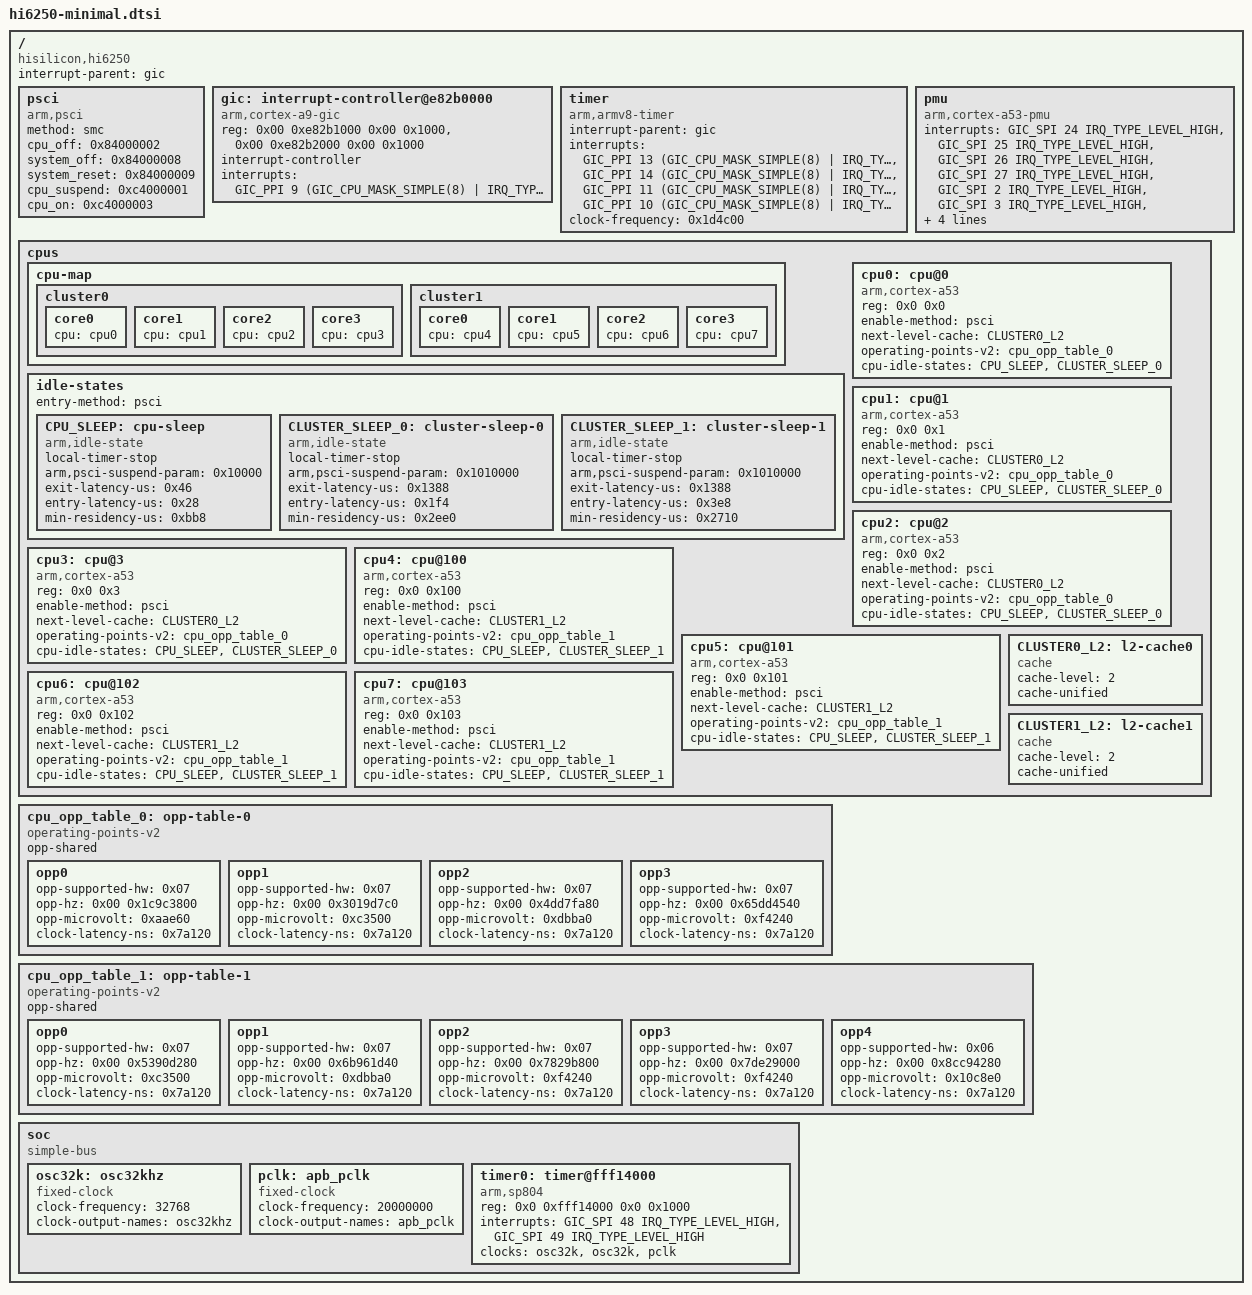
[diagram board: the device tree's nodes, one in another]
// SPDX-License-Identifier: GPL-2.0
/*
 * Minimal device tree of Hisilicon Hi6250 SoC
 *
 * Mostly by @pentiumpro:matrix.org
 */

#include <dt-bindings/interrupt-controller/arm-gic.h>
#include <dt-bindings/gpio/gpio.h>

/ {
	compatible = "hisilicon,hi6250";
	interrupt-parent = <&gic>;
	#address-cells = <2>;
	#size-cells = <2>;

	psci {
		compatible = "arm,psci";
		method = "smc";
		cpu_off = <0x84000002>;
		system_off = <0x84000008>;
		system_reset = <0x84000009>;
		cpu_suspend = <0xc4000001>;
		cpu_on = <0xc4000003>;
	};

	gic: interrupt-controller@e82b0000 {
		compatible = "arm,cortex-a9-gic";
		reg = <0x00 0xe82b1000 0x00 0x1000>,
			  <0x00 0xe82b2000 0x00 0x1000>;
		#interrupt-cells = <0x03>;
		#size-cells = <0x02>;
		#address-cells = <0x02>;
		interrupt-controller;
		interrupts = <GIC_PPI 9 (GIC_CPU_MASK_SIMPLE(8) | IRQ_TYPE_LEVEL_HIGH)>;
		ranges;
	};

	timer {
		compatible = "arm,armv8-timer";
		interrupt-parent = <&gic>;
		interrupts = <GIC_PPI 13 (GIC_CPU_MASK_SIMPLE(8) | IRQ_TYPE_LEVEL_LOW)>,
				 <GIC_PPI 14 (GIC_CPU_MASK_SIMPLE(8) | IRQ_TYPE_LEVEL_LOW)>,
				 <GIC_PPI 11 (GIC_CPU_MASK_SIMPLE(8) | IRQ_TYPE_LEVEL_LOW)>,
				 <GIC_PPI 10 (GIC_CPU_MASK_SIMPLE(8) | IRQ_TYPE_LEVEL_LOW)>;
		clock-frequency = <0x1d4c00>;
	};

	pmu {
		compatible = "arm,cortex-a53-pmu";
		interrupts = <GIC_SPI 24 IRQ_TYPE_LEVEL_HIGH>,
			<GIC_SPI 25 IRQ_TYPE_LEVEL_HIGH>,
			<GIC_SPI 26 IRQ_TYPE_LEVEL_HIGH>,
			<GIC_SPI 27 IRQ_TYPE_LEVEL_HIGH>,
			<GIC_SPI 2 IRQ_TYPE_LEVEL_HIGH>,
			<GIC_SPI 3 IRQ_TYPE_LEVEL_HIGH>,
			<GIC_SPI 4 IRQ_TYPE_LEVEL_HIGH>,
			<GIC_SPI 5 IRQ_TYPE_LEVEL_HIGH>;
		interrupt-affinity = <&cpu0>,
			<&cpu1>,
			<&cpu2>,
			<&cpu3>,
			<&cpu4>,
			<&cpu5>,
			<&cpu6>,
			<&cpu7>;
	};
	
	cpus {
		#address-cells = <2>;
		#size-cells = <0>;

		cpu-map {
			cluster0 {
				core0 {
					cpu = <&cpu0>;
				};
				core1 {
					cpu = <&cpu1>;
				};
				core2 {
					cpu = <&cpu2>;
				};
				core3 {
					cpu = <&cpu3>;
				};
			};
			cluster1 {
				core0 {
					cpu = <&cpu4>;
				};
				core1 {
					cpu = <&cpu5>;
				};
				core2 {
					cpu = <&cpu6>;
				};
				core3 {
					cpu = <&cpu7>;
				};
			};
		};

		idle-states {
			entry-method = "psci";

			CPU_SLEEP: cpu-sleep {
				compatible = "arm,idle-state";
				local-timer-stop;
				arm,psci-suspend-param = <0x10000>;
				exit-latency-us = <0x46>;
				entry-latency-us = <0x28>;
				min-residency-us = <0xbb8>;
			};

			CLUSTER_SLEEP_0: cluster-sleep-0 {
				compatible = "arm,idle-state";
				local-timer-stop;
				arm,psci-suspend-param = <0x1010000>;
				exit-latency-us = <0x1388>;
				entry-latency-us = <0x1f4>;
				min-residency-us = <0x2ee0>;
			};
			
			CLUSTER_SLEEP_1: cluster-sleep-1 {
				compatible = "arm,idle-state";
				local-timer-stop;
				arm,psci-suspend-param = <0x1010000>;
				exit-latency-us = <0x1388>;
				entry-latency-us = <0x3e8>;
				min-residency-us = <0x2710>;
			};
		};

		cpu0: cpu@0 {
			compatible = "arm,cortex-a53";
			device_type = "cpu";
			reg = <0x0 0x0>;
			enable-method = "psci";
			next-level-cache = <&CLUSTER0_L2>;
			// clocks = <&stub_clock HI6250_CLK_STUB_CLUSTER0>;
			operating-points-v2 = <&cpu_opp_table_0>;
			cpu-idle-states = <&CPU_SLEEP &CLUSTER_SLEEP_0>;
			// #cooling-cells = <3>; /* min followed by max */
		};

		cpu1: cpu@1 {
			compatible = "arm,cortex-a53";
			device_type = "cpu";
			reg = <0x0 0x1>;
			enable-method = "psci";
			next-level-cache = <&CLUSTER0_L2>;
			// clocks = <&stub_clock HI6250_CLK_STUB_CLUSTER0>;
			operating-points-v2 = <&cpu_opp_table_0>;
			cpu-idle-states = <&CPU_SLEEP &CLUSTER_SLEEP_0>;
			// #cooling-cells = <3>; /* min followed by max */
		};

		cpu2: cpu@2 {
			compatible = "arm,cortex-a53";
			device_type = "cpu";
			reg = <0x0 0x2>;
			enable-method = "psci";
			next-level-cache = <&CLUSTER0_L2>;
			// clocks = <&stub_clock HI6250_CLK_STUB_CLUSTER0>;
			operating-points-v2 = <&cpu_opp_table_0>;
			cpu-idle-states = <&CPU_SLEEP &CLUSTER_SLEEP_0>;
			// #cooling-cells = <3>; /* min followed by max */
			// dynamic-power-coefficient = <311>;
		};

		cpu3: cpu@3 {
			compatible = "arm,cortex-a53";
			device_type = "cpu";
			reg = <0x0 0x3>;
			enable-method = "psci";
			next-level-cache = <&CLUSTER0_L2>;
			// clocks = <&stub_clock HI6250_CLK_STUB_CLUSTER0>;
			operating-points-v2 = <&cpu_opp_table_0>;
			cpu-idle-states = <&CPU_SLEEP &CLUSTER_SLEEP_0>;
			// #cooling-cells = <3>; /* min followed by max */
			// dynamic-power-coefficient = <311>;
		};

		cpu4: cpu@100 {
			compatible = "arm,cortex-a53";
			device_type = "cpu";
			reg = <0x0 0x100>;
			enable-method = "psci";
			next-level-cache = <&CLUSTER1_L2>;
			// clocks = <&stub_clock HI6250_CLK_STUB_CLUSTER1>;
			operating-points-v2 = <&cpu_opp_table_1>;
			cpu-idle-states = <&CPU_SLEEP &CLUSTER_SLEEP_1>;
			// #cooling-cells = <3>; /* min followed by max */
		};

		cpu5: cpu@101 {
			compatible = "arm,cortex-a53";
			device_type = "cpu";
			reg = <0x0 0x101>;
			enable-method = "psci";
			next-level-cache = <&CLUSTER1_L2>;
			// clocks = <&stub_clock HI6250_CLK_STUB_CLUSTER1>;
			operating-points-v2 = <&cpu_opp_table_1>;
			cpu-idle-states = <&CPU_SLEEP &CLUSTER_SLEEP_1>;
			// #cooling-cells = <3>; /* min followed by max */
		};

		cpu6: cpu@102 {
			compatible = "arm,cortex-a53";
			device_type = "cpu";
			reg = <0x0 0x102>;
			enable-method = "psci";
			next-level-cache = <&CLUSTER1_L2>;
			// clocks = <&stub_clock HI6250_CLK_STUB_CLUSTER1>;
			operating-points-v2 = <&cpu_opp_table_1>;
			cpu-idle-states = <&CPU_SLEEP &CLUSTER_SLEEP_1>;
			// #cooling-cells = <3>; /* min followed by max */
		};

		cpu7: cpu@103 {
			compatible = "arm,cortex-a53";
			device_type = "cpu";
			reg = <0x0 0x103>;
			enable-method = "psci";
			next-level-cache = <&CLUSTER1_L2>;
			// clocks = <&stub_clock HI6250_CLK_STUB_CLUSTER1>;
			operating-points-v2 = <&cpu_opp_table_1>;
			cpu-idle-states = <&CPU_SLEEP &CLUSTER_SLEEP_1>;
			// #cooling-cells = <3>; /* min followed by max */
		};

		CLUSTER0_L2: l2-cache0 {
			compatible = "cache";
			cache-level = <2>;
			cache-unified;
		};

		CLUSTER1_L2: l2-cache1 {
			compatible = "cache";
			cache-level = <2>;
			cache-unified;
		};
	};

	cpu_opp_table_0: opp-table-0 {
		opp-shared;
		compatible = "operating-points-v2";

		opp0 {
			opp-supported-hw = <0x07>;
			opp-hz = <0x00 0x1c9c3800>;
			opp-microvolt = <0xaae60>;
			clock-latency-ns = <0x7a120>;
		};

		opp1 {
			opp-supported-hw = <0x07>;
			opp-hz = <0x00 0x3019d7c0>;
			opp-microvolt = <0xc3500>;
			clock-latency-ns = <0x7a120>;
		};

		opp2 {
			opp-supported-hw = <0x07>;
			opp-hz = <0x00 0x4dd7fa80>;
			opp-microvolt = <0xdbba0>;
			clock-latency-ns = <0x7a120>;
		};

		opp3 {
			opp-supported-hw = <0x07>;
			opp-hz = <0x00 0x65dd4540>;
			opp-microvolt = <0xf4240>;
			clock-latency-ns = <0x7a120>;
		};
	};

	cpu_opp_table_1: opp-table-1 {
		opp-shared;
		compatible = "operating-points-v2";

		opp0 {
			opp-supported-hw = <0x07>;
			opp-hz = <0x00 0x5390d280>;
			opp-microvolt = <0xc3500>;
			clock-latency-ns = <0x7a120>;
		};

		opp1 {
			opp-supported-hw = <0x07>;
			opp-hz = <0x00 0x6b961d40>;
			opp-microvolt = <0xdbba0>;
			clock-latency-ns = <0x7a120>;
		};

		opp2 {
			opp-supported-hw = <0x07>;
			opp-hz = <0x00 0x7829b800>;
			opp-microvolt = <0xf4240>;
			clock-latency-ns = <0x7a120>;
		};

		opp3 {
			opp-supported-hw = <0x07>;
			opp-hz = <0x00 0x7de29000>;
			opp-microvolt = <0xf4240>;
			clock-latency-ns = <0x7a120>;
		};

		opp4 {
			opp-supported-hw = <0x06>;
			opp-hz = <0x00 0x8cc94280>;
			opp-microvolt = <0x10c8e0>;
			clock-latency-ns = <0x7a120>;
		};
	};

	soc {
		compatible = "simple-bus";
		#address-cells = <2>;
		#size-cells = <2>;
		ranges;
		
		osc32k: osc32khz {
			compatible = "fixed-clock";
			#clock-cells = <0>;
			clock-frequency = <32768>;
			clock-output-names = "osc32khz";
		};
	
		pclk: apb_pclk {
			compatible = "fixed-clock";
			#clock-cells = <0>;
			clock-frequency = <20000000>;
			clock-output-names = "apb_pclk";
		};
		
		timer0: timer@fff14000 {
			compatible = "arm,sp804";
			reg = <0x0 0xfff14000 0x0 0x1000>;
			interrupts = <GIC_SPI 48 IRQ_TYPE_LEVEL_HIGH>,
			<GIC_SPI 49 IRQ_TYPE_LEVEL_HIGH>;
			clocks = <&osc32k &osc32k &pclk>;
			clock-names = "osc32khz", "osc32khz", "apb_pclk";
		};
	};
};
